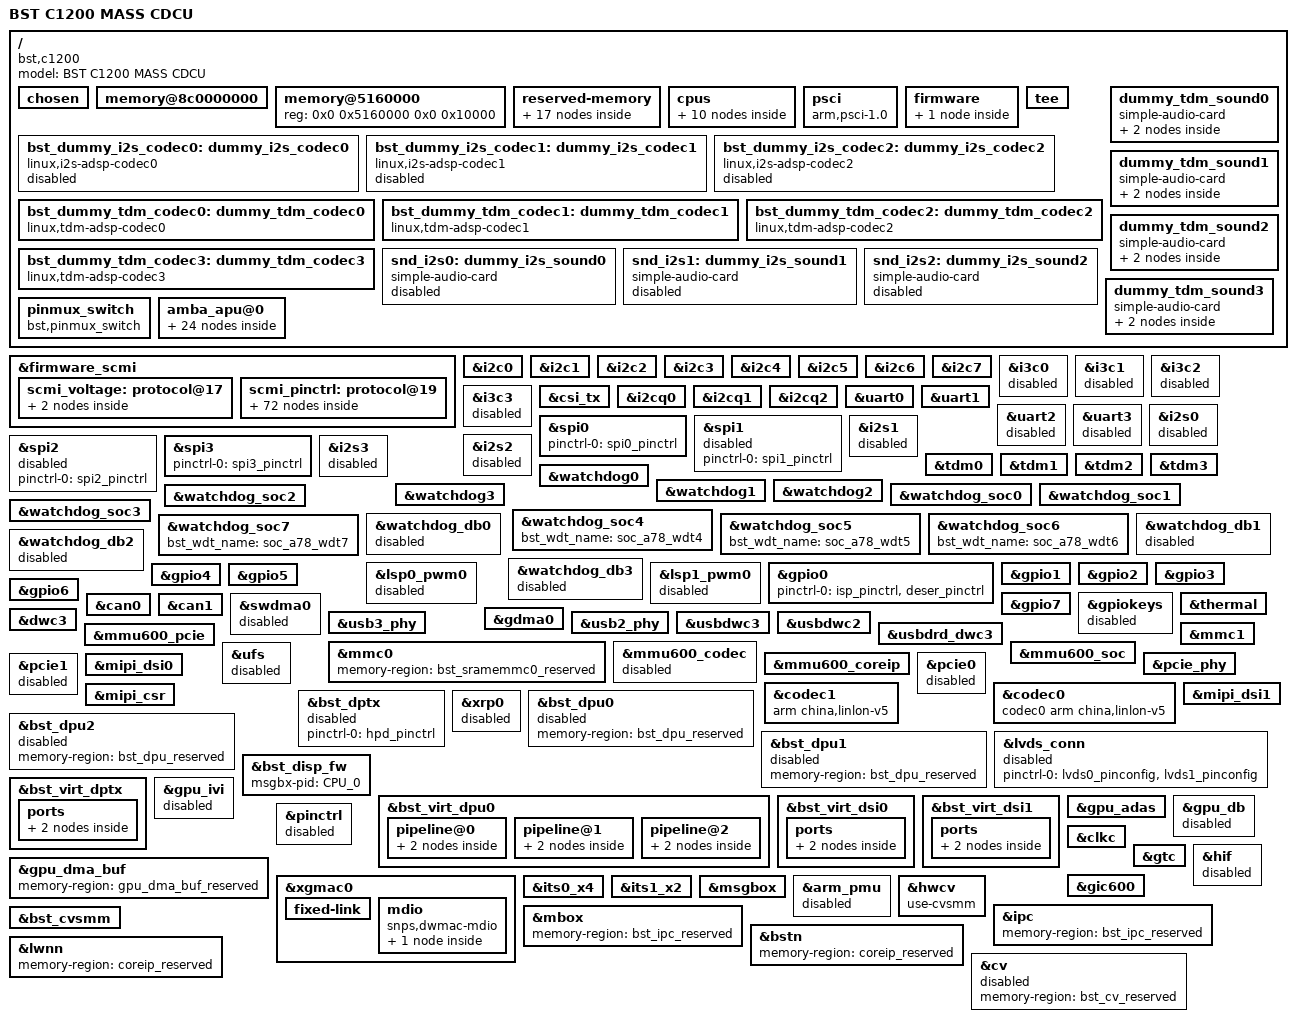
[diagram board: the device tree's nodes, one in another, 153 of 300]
// SPDX-License-Identifier: GPL-2.0+
/dts-v1/;
#include "bstc1200.dtsi"

/ {
	compatible = "bst,c1200";
	model = "BST C1200 MASS CDCU";

	chosen {
		bootargs = "earlycon=uart8250,mmio32,0x20008000 console=ttyS0,115200n8 rdinit=/sbin/init root=/dev/ram rw init=/linuxrc rodata=n";
		stdout-path = "uart0";
	};

	memory@8c0000000 {
		device_type = "memory";
		reg = < 0x8 0x10000000 0x0 0x30000000
			0x8 0xc0000000 0x1 0x0
			0xc 0x0 0x0 0x40000000
			0x8 0x254000 0x0 0x1000
			0x8 0x151000 0x0 0x1000
			0x8 0x1400000 0x0 0x1000000
			0x8 0x50000000 0x0 0x03000000
			0xc 0x50000000 0x0 0x03000000
		>;
	};

	// eMMC 64K
	memory@5160000 {
		device_type = "memory";
		reg = <0x0 0x5160000 0x0 0x10000>;
	};

	reserved-memory {
		#address-cells = <2>;
		#size-cells = <2>;
		ranges;

		scmi_buf_reserved: scmi_buf@800151000 {
			compatible = "shared-dma-pool";
			reg = <0x8 0x151000 0x0 0x1000>;
			no-map;
		};



		bst_nor_flash_code_reserved: bst_nor_flash@800130000 {
			compatible = "shared-dma-pool";
			reg = <0x8 0x130000 0x0 0x10000>;
			no-map;
		};


		bst_sramemmc0_reserved: bst_sramemmc0@5160000{
			compatible = "shared-dma-pool";
			reg = <0x0 0x5160000 0x0 0x10000>;
			no-map;
		};


		bst_sramemmc1_reserved: bst_sramemmc0@5170000{
			compatible = "shared-dma-pool";
			reg = <0x0 0x5170000 0x0 0x10000>;
			no-map;
		};

		bst_dpu_reserved: bst_dpu_cma@940000000 {
			compatible = "shared-dma-pool";
			reg = <0x9 0x40000000 0x0 0x4000000>;
			reusable;
		};

		/* gpu memory pool */
		gpu_dma_buf_reserved: gpu_cma@944000000 {
			compatible = "shared-dma-pool";
			align-shift = <8>;
			reg = <0x9 0x44000000 0x0 0x8000000>;
			reusable;
		};

		bst_ipc_reserved: bst_ipc@80ff00000 {
			compatible = "shared-dma-pool";
			reg = <0x8 0x0ff00000 0x0 0x100000>;
			no-map;
		};

		bstn_fw_code_reserved: bstn@810000000 {
			compatible = "shared-dma-pool";
			reg = <0x8 0x10000000 0x0 0x2000000>;
			no-map;
		};

		bst_lwnn_fw_code_reserved: bst_lwnn@812000000 {
			compatible = "shared-dma-pool";
			reg = <0x8 0x12000000 0x0 0x8000000>;
			no-map;
		};

		bst_cv_reserved: bst_cv_cma@81a000000 {
			compatible = "shared-dma-pool";
			reg = <0x8 0x1a000000 0x0 0x2000000>;
			align-shift = <8>;
			reusable;
		};

		bst_debug_reserved: bst_debug@81c000000 {
			compatible = "shared-dma-pool";
			reg = <0x8 0x1c000000 0x0 0x5000000>;
			no-map;
		};

		/* coreip public memory pool */
		coreip_reserved: coreip_pub_cma@c00000000 {
			compatible = "shared-dma-pool";
			align-shift = <8>;
			reg = <0xc 0x0 0x0 0x40000000>;
			reusable;
linux,cma-heap;
		};

		/* Reserved for exchange message between driver and firmware */
		isp_fw_msg_rsv: bst_isp_msg@821000000 {
			reg = <0x8 0x21000000 0x0 0x1000000>;
			no-map;
		};

		/* Reserved exclusively for firmware */
		isp_fw_buf_rsv: bst_isp_buf@822000000 {
			reg = <0x8 0x22000000 0x0 0x15000000>;
			no-map;
		};

		/*reserved for global secure dmabuf */
		global_dmabuf_secure_reserved: global_secure_dmabuf@850000000 {
			compatible = "shared-dma-pool";
			reg = <0x8 0x50000000 0x0 0x03000000
                   0xc 0x50000000 0x0 0x03000000
			>;
			no-map;
		};
		/*reserved for global normal dmabuf */
		global_dmabuf_normal_reserved: global_normal_dmabuf@837000000 {
			compatible = "shared-dma-pool";
			reg = <0x8 0x37000000 0x0 0x09000000>;
			no-map;
		};

		bst_optee_reserved: bst_optee@801400000 {
			compatible = "shared-dma-pool";
			reg = <0x8 0x1400000 0x0 0x1000000>;
			no-map;
		};
	};


/****************************************************************************************/
/*	c0_lockstep/c1_split	1 + 5: c0 0x0 + c0 0x100 \ c1 0x0 ~ 0x300
 *	c0_lockstep/c1_lockstep	1 + 3: c0 0x0 + c0 0x100 \ c1 0x0 ~ 0x100
 *	split			2 + 6: c0 0x0 ~ 0x100 + c0 0x200 ~ 0x300 \ c1 0x0 ~ 0x300
 *	split			4 + 4: c0 0x0 ~ 0x300 + c1 0x0 ~ 0x300
 */
/****************************************************************************************/
	cpus {
		#address-cells = <1>;
		#size-cells = <0>;

		/* cluster 0 */
		cpu_l0: cpu@0 {
			compatible = "arm,cortex-a78", "arm,armv8";
			device_type = "cpu";
			enable-method = "psci";
			next-level-cache = <&l2_0>;
			reg = <0x0>;
			freq-domain = <&cpufreq 0>;
		};
		cpu_l1: cpu@1 {
			compatible = "arm,cortex-a78", "arm,armv8";
			device_type = "cpu";
			enable-method = "psci";
			next-level-cache = <&l2_0>;
			reg = <0x100>;
			freq-domain = <&cpufreq 0>;
		};
		cpu_l2: cpu@2 {
			compatible = "arm,cortex-a78", "arm,armv8";
			device_type = "cpu";
			enable-method = "psci";
			next-level-cache = <&l2_0>;
			reg = <0x200>;
			freq-domain = <&cpufreq 0>;
		};
		cpu_l3: cpu@3 {
			compatible = "arm,cortex-a78", "arm,armv8";
			device_type = "cpu";
			enable-method = "psci";
			next-level-cache = <&l2_0>;
			reg = <0x300>;
			freq-domain = <&cpufreq 0>;
		};
		l2_0: l2-cache-0 {
			compatible = "cache";
		};
                /* cluster 1 */
                cpu_b0: cpu@100 {
                        compatible = "arm,cortex-a78", "arm,armv8";
                        device_type = "cpu";
                        enable-method = "psci";
                        next-level-cache = <&l2_1>;
                        reg = <0x10000>;
			freq-domain = <&cpufreq 1>;
                };
                cpu_b1: cpu@101 {
                        compatible = "arm,cortex-a78", "arm,armv8";
                        device_type = "cpu";
                        enable-method = "psci";
                        next-level-cache = <&l2_1>;
                        reg = <0x10100>;
			freq-domain = <&cpufreq 1>;
                };
                cpu_b2: cpu@102 {
                        compatible = "arm,cortex-a78", "arm,armv8";
                        device_type = "cpu";
                        enable-method = "psci";
                        next-level-cache = <&l2_1>;
                        reg = <0x10200>;
			freq-domain = <&cpufreq 1>;
                };
                cpu_b3: cpu@103 {
                        compatible = "arm,cortex-a78", "arm,armv8";
                        device_type = "cpu";
                        enable-method = "psci";
                        next-level-cache = <&l2_1>;
                        reg = <0x10300>;
			freq-domain = <&cpufreq 1>;
                };

                l2_1: l2-cache-1 {
                        compatible = "cache";
                };

	};

	psci {
		compatible	= "arm,psci-1.0";
		method		= "smc";
		cpu_on		= <0xC4000003>;
		cpu_off		= <0x84000002>;
		cpu_suspend	= <0xC4000001>;
	};



	firmware {
		optee {
                compatible = "linaro,optee-tz";
                method = "smc";
                chip-number = <2>;
        };
	};

	tee {
		#address-cells = <0x2>;
		#size-cells = <0x2>;
		reg = <0x0 0x18060000 0x0 0x1f000>;
		memory-region = <&bst_optee_reserved>;
		mbox-names = "bst-mbox";
		chip-number = <2>;
	};

    bst_dummy_i2s_codec0:dummy_i2s_codec0 {
         compatible = "linux,i2s-adsp-codec0";
         #sound-dai-cells = <0>;
         status = "disable";
    };
    bst_dummy_i2s_codec1:dummy_i2s_codec1 {
         compatible = "linux,i2s-adsp-codec1";
         #sound-dai-cells = <0>;
         status = "disable";
    };

    bst_dummy_i2s_codec2:dummy_i2s_codec2 {
         compatible = "linux,i2s-adsp-codec2";
         #sound-dai-cells = <0>;
         status = "disable";
    };

    bst_dummy_tdm_codec0:dummy_tdm_codec0 {
         compatible = "linux,tdm-adsp-codec0";
         #sound-dai-cells = <0>;
         status = "okay";
    };

    bst_dummy_tdm_codec1:dummy_tdm_codec1 {
         compatible = "linux,tdm-adsp-codec1";
         #sound-dai-cells = <0>;
         status = "okay";
    };

    bst_dummy_tdm_codec2:dummy_tdm_codec2 {
         compatible = "linux,tdm-adsp-codec2";
         #sound-dai-cells = <0>;
         status = "okay";
    };

    bst_dummy_tdm_codec3:dummy_tdm_codec3 {
         compatible = "linux,tdm-adsp-codec3";
         #sound-dai-cells = <0>;
         status = "okay";
    };

    snd_i2s0:dummy_i2s_sound0 {
        status = "disable";
        compatible = "simple-audio-card";
        simple-audio-card,format = "i2s";
        simple-audio-card,name = "everest,dummy-codec-i2s0";
        simple-audio-card,mclk-fs = <256>;
        //simple-audio-card,bitclock-master = <&sndcodec0>;
        //simple-audio-card,frame-master = <&sndcodec0>;
    };

    snd_i2s1:dummy_i2s_sound1 {
        status = "disable";
        compatible = "simple-audio-card";
        simple-audio-card,format = "i2s";
        simple-audio-card,name = "everest,dummy-codec-i2s1";
        simple-audio-card,mclk-fs = <256>;
    };

    snd_i2s2:dummy_i2s_sound2 {
        status = "disable";
        compatible = "simple-audio-card";
        simple-audio-card,format = "i2s";
        simple-audio-card,name = "everest,dummy-codec-i2s2";
        simple-audio-card,mclk-fs = <256>;
        //simple-audio-card,bitclock-master = <&sndcodec1>;
        //simple-audio-card,frame-master = <&sndcodec1>;
    };

    dummy_tdm_sound0 {
        status = "okay";
        compatible = "simple-audio-card";
        simple-audio-card,format = "i2s";
        simple-audio-card,name = "everest,dummy-codec-tdm0";
        simple-audio-card,mclk-fs = <256>;

        simple-audio-card,cpu {
            sound-dai = <&tdm0>;
        };

        simple-audio-card,codec {
            sound-dai = <&bst_dummy_tdm_codec0>;
        };
    };

    dummy_tdm_sound1 {
        status = "okay";
        compatible = "simple-audio-card";
        simple-audio-card,format = "i2s";
        simple-audio-card,name = "everest,dummy-codec-tdm1";
        simple-audio-card,mclk-fs = <256>;

        simple-audio-card,cpu {
            sound-dai = <&tdm1>;
        };

        simple-audio-card,codec {
            sound-dai = <&bst_dummy_tdm_codec1>;
        };
    };

    dummy_tdm_sound2 {
        status = "okay";
        compatible = "simple-audio-card";
        simple-audio-card,format = "i2s";
        simple-audio-card,name = "everest,dummy-codec-tdm2";
        simple-audio-card,mclk-fs = <256>;

        simple-audio-card,cpu {
            sound-dai = <&tdm2>;
        };

        simple-audio-card,codec {
            sound-dai = <&bst_dummy_tdm_codec2>;
        };
    };

    dummy_tdm_sound3 {
        status = "okay";
        compatible = "simple-audio-card";
        simple-audio-card,format = "i2s";
        simple-audio-card,name = "everest,dummy-codec-tdm3";
        simple-audio-card,mclk-fs = <256>;

        simple-audio-card,cpu {
            sound-dai = <&tdm3>;
        };

        simple-audio-card,codec {
            sound-dai = <&bst_dummy_tdm_codec3>;
        };
    };
	pinmux_switch {
		compatible = "bst,pinmux_switch";
		status = "okay";

		pinctrl-names = "switch_on", "switch_off", \
						"i2c0_mode", "i3c0_mode", \
						"i2c1_mode", "i3c1_mode", \
						"i2c2_mode", "i3c2_mode", \
						"i2c3_mode", "i3c3_mode", \
						"i2c4_mode", "i3c40_mode", \
						"i2c5_mode", "i2cq0_mode", \
						"i2c6_mode", "i2cq1_mode", \
						"i2c7_mode", "i2cq2_mode", \
						"i2s0_on", "i2s1_on", "i2s2_on", \
						"tdm0_on", "tdm1_on", "tdm2_on", "tdm3_on";
		pinctrl-0 = <&debug1_pinctrl>;
		pinctrl-1 = <&debug2_pinctrl>;
		pinctrl-2 = <&i2c0_pinctrl>;
		pinctrl-3 = <&i3c0_pinctrl>;
		pinctrl-4 = <&i2c1_pinctrl>;
		pinctrl-5 = <&i3c1_pinctrl>;
		pinctrl-6 = <&i2c2_pinctrl>;
		pinctrl-7 = <&i3c2_pinctrl>;
		pinctrl-8 = <&i2c3_pinctrl>;
		pinctrl-9 = <&i3c3_pinctrl>;
		pinctrl-10 = <&i2c4_pinctrl>;
		pinctrl-11 = <&i3c40_pinctrl>;
		pinctrl-12 = <&i2c5_pinctrl>;
		pinctrl-13 = <&i2cq0_pinctrl>;
		pinctrl-14 = <&i2c6_pinctrl>;
		pinctrl-15 = <&i2cq1_pinctrl>;
		pinctrl-16 = <&i2c7_pinctrl>;
		pinctrl-17 = <&i2cq2_pinctrl>;
		pinctrl-18 = <&i2s0_pinctrl>;
		pinctrl-19 = <&i2s1_pinctrl>;
		pinctrl-20 = <&i2s2_pinctrl>;
		pinctrl-21 = <&tdm0_pinctrl>;
		pinctrl-22 = <&tdm1_pinctrl>;
		pinctrl-23 = <&tdm2_pinctrl>;
		pinctrl-24 = <&tdm3_pinctrl>;
	};

	amba_apu@0 {
		//i2c cycleloop mode A start
		i2ca0: i2ca0 {
			#address-cells = <1>;
			#size-cells = <0>;
			compatible = "snps,designware-i2c";
			reg = <0x0 0x20001000 0 0x1000>;
			interrupt-parent = <&gic600>;
			interrupts = <GIC_SPI 202 IRQ_TYPE_LEVEL_HIGH>;
			clock-frequency = <3400000>;
			i2c-sda-hold-time-ns = <10>;
			i2c-sda-falling-time-ns = <5>;
			i2c-scl-falling-time-ns = <5>;
			clocks= <&scmi_clk GATE_LSP0_I2C0_PCLK_EN>,
				<&scmi_clk GATE_LSP0_I2C0_WCLK_EN>;
			clock-names = "pclk","wclk";
			resets = <&scmi_reset RST_LSP0_I2C0_WCLK_SW>;
			reset-names = "i2c0_reset";
			i2c-nr = <0>;
			status = "disable";
		};

		i2ca1: i2ca1 {
			#address-cells = <1>;
			#size-cells = <0>;
			compatible = "snps,designware-i2c";
			reg = <0x0 0x20002000 0 0x1000>;
			interrupt-parent = <&gic600>;
			interrupts = <GIC_SPI 203 IRQ_TYPE_LEVEL_HIGH>;
			clock-frequency = <3400000>;
			i2c-sda-hold-time-ns = <10>;
			i2c-sda-falling-time-ns = <5>;
			i2c-scl-falling-time-ns = <5>;
			clocks= <&scmi_clk GATE_LSP0_I2C1_PCLK_EN>,
				<&scmi_clk GATE_LSP0_I2C1_WCLK_EN>;
			clock-names = "pclk","wclk";
			resets = <&scmi_reset RST_LSP0_I2C1_WCLK_SW>;
			reset-names = "i2c0_reset";
			i2c-nr = <1>;
			status = "disable";
			i2c-slave-eeprom@64 {
				compatible = "slave-24c02";
				reg = <0x40000064>;
			};
		};

		i2ca2: i2ca2 {
			#address-cells = <1>;
			#size-cells = <0>;
			compatible = "snps,designware-i2c";
			reg = <0x0 0x20003000 0 0x1000>;
			interrupt-parent = <&gic600>;
			interrupts = <GIC_SPI 204 IRQ_TYPE_LEVEL_HIGH>;
			clock-frequency = <3400000>;
			i2c-sda-hold-time-ns = <10>;
			i2c-sda-falling-time-ns = <5>;
			i2c-scl-falling-time-ns = <5>;
			clocks= <&scmi_clk GATE_LSP0_I2C2_PCLK_EN>,
				<&scmi_clk GATE_LSP0_I2C2_WCLK_EN>;
			clock-names = "pclk","wclk";
			resets = <&scmi_reset RST_LSP0_I2C2_WCLK_SW>;
			reset-names = "i2c0_reset";

			i2c-nr = <2>;
			status = "disable";
		};

		i2ca3: i2ca3 {
			#address-cells = <1>;
			#size-cells = <0>;
			compatible = "snps,designware-i2c";
			reg = <0x0 0x20004000 0 0x1000>;
			interrupt-parent = <&gic600>;
			interrupts = <GIC_SPI 205 IRQ_TYPE_LEVEL_HIGH>;
			clock-frequency = <3400000>;
			i2c-sda-hold-time-ns = <10>;
			i2c-sda-falling-time-ns = <5>;
			i2c-scl-falling-time-ns = <5>;
			clocks= <&scmi_clk GATE_LSP0_I2C3_PCLK_EN>,
				<&scmi_clk GATE_LSP0_I2C3_WCLK_EN>;
			clock-names = "pclk","wclk";
			resets = <&scmi_reset RST_LSP0_I2C3_WCLK_SW>;
			reset-names = "i2c0_reset";
			i2c-nr = <3>;
			status = "disable";
			i2c-slave-eeprom@64 {
				compatible = "slave-24c02";
				reg = <0x40000064>;
			};
		};

		i2ca4: i2ca4 {
			#address-cells = <1>;
			#size-cells = <0>;
			compatible = "snps,designware-i2c";
			reg = <0x0 0x20021000 0 0x1000>;
			interrupt-parent = <&gic600>;
			interrupts = <GIC_SPI 237 IRQ_TYPE_LEVEL_HIGH>;
			clock-frequency = <3400000>;
			i2c-sda-hold-time-ns = <10>;
			i2c-sda-falling-time-ns = <5>;
			i2c-scl-falling-time-ns = <5>;
			clocks= <&scmi_clk GATE_LSP1_I2C0_PCLK_EN>,
				<&scmi_clk GATE_LSP1_I2C0_WCLK_EN>;
			clock-names = "pclk","wclk";
			resets = <&scmi_reset RST_LSP1_I2C0_WCLK_SW>;
			reset-names = "i2c0_reset";
			i2c-nr = <4>;
			status = "disable";
		};

		i2ca5: i2ca5 {
			#address-cells = <1>;
			#size-cells = <0>;
			compatible = "snps,designware-i2c";
			reg = <0x0 0x20022000 0 0x1000>;
			interrupt-parent = <&gic600>;
			interrupts = <GIC_SPI 238 IRQ_TYPE_LEVEL_HIGH>;
			clock-frequency = <3400000>;
			i2c-sda-hold-time-ns = <10>;
			i2c-sda-falling-time-ns = <5>;
			i2c-scl-falling-time-ns = <5>;
			clocks= <&scmi_clk GATE_LSP1_I2C1_PCLK_EN>,
				<&scmi_clk GATE_LSP1_I2C1_WCLK_EN>;
			clock-names = "pclk","wclk";
			resets = <&scmi_reset RST_LSP1_I2C1_WCLK_SW>;
			reset-names = "i2c0_reset";
			i2c-nr = <5>;
			status = "disable";
			i2c-slave-eeprom@64 {
				compatible = "slave-24c02";
				reg = <0x40000064>;
			};
		};

		i2ca6: i2ca6 {
			#address-cells = <1>;
			#size-cells = <0>;
			compatible = "snps,designware-i2c";
			reg = <0x0 0x20023000 0 0x1000>;
			interrupt-parent = <&gic600>;
			interrupts = <GIC_SPI 239 IRQ_TYPE_LEVEL_HIGH>;
			clock-frequency = <3400000>;
			i2c-sda-hold-time-ns = <10>;
			i2c-sda-falling-time-ns = <5>;
			i2c-scl-falling-time-ns = <5>;
			clocks= <&scmi_clk GATE_LSP1_I2C2_PCLK_EN>,
			<&scmi_clk GATE_LSP1_I2C2_WCLK_EN>;
			clock-names = "pclk","wclk";
			resets = <&scmi_reset RST_LSP1_I2C2_WCLK_SW>;
			reset-names = "i2c0_reset";
			i2c-nr = <6>;
			status = "disable";
		};

		i2ca7: i2ca7 {
			#address-cells = <1>;
			#size-cells = <0>;
			compatible = "snps,designware-i2c";
			reg = <0x0 0x20024000 0 0x1000>;
			interrupt-parent = <&gic600>;
			interrupts = <GIC_SPI 240 IRQ_TYPE_LEVEL_HIGH>;
			clock-frequency = <3400000>;
			i2c-sda-hold-time-ns = <10>;
			i2c-sda-falling-time-ns = <5>;
			i2c-scl-falling-time-ns = <5>;
			clocks= <&scmi_clk GATE_LSP1_I2C3_PCLK_EN>,
			<&scmi_clk GATE_LSP1_I2C3_WCLK_EN>;
			clock-names = "pclk","wclk";
			resets = <&scmi_reset RST_LSP1_I2C3_WCLK_SW>;
			reset-names = "i2c0_reset";
			i2c-nr = <7>;
			status = "disable";
			i2c-slave-eeprom@64 {
				compatible = "slave-24c02";
				reg = <0x40000064>;
			};
		};
		//i2c cycleloop mode A end
		//i2c cycleloop mode B start
		i2cb0: i2cb0 {
			#address-cells = <1>;
			#size-cells = <0>;
			compatible = "snps,designware-i2c";
			reg = <0x0 0x20001000 0 0x1000>;
			interrupt-parent = <&gic600>;
			interrupts = <GIC_SPI 202 IRQ_TYPE_LEVEL_HIGH>;
			clock-frequency = <3400000>;
			i2c-sda-hold-time-ns = <10>;
			i2c-sda-falling-time-ns = <5>;
			i2c-scl-falling-time-ns = <5>;
			clocks= <&scmi_clk GATE_LSP0_I2C0_PCLK_EN>,
				<&scmi_clk GATE_LSP0_I2C0_WCLK_EN>;
			clock-names = "pclk","wclk";
			resets = <&scmi_reset RST_LSP0_I2C0_WCLK_SW>;
			reset-names = "i2c0_reset";
			i2c-nr = <0>;
			status = "disable";
			i2c-slave-eeprom@64 {
				compatible = "slave-24c02";
				reg = <0x40000064>;
			};
		};

		i2cb1: i2cb1 {
			#address-cells = <1>;
			#size-cells = <0>;
			compatible = "snps,designware-i2c";
			reg = <0x0 0x20002000 0 0x1000>;
			interrupt-parent = <&gic600>;
			interrupts = <GIC_SPI 203 IRQ_TYPE_LEVEL_HIGH>;
			clock-frequency = <3400000>;
			i2c-sda-hold-time-ns = <10>;
			i2c-sda-falling-time-ns = <5>;
			i2c-scl-falling-time-ns = <5>;
			clocks= <&scmi_clk GATE_LSP0_I2C1_PCLK_EN>,
			<&scmi_clk GATE_LSP0_I2C1_WCLK_EN>;
			clock-names = "pclk","wclk";
			resets = <&scmi_reset RST_LSP0_I2C1_WCLK_SW>;
			reset-names = "i2c0_reset";
			i2c-nr = <1>;
			status = "disable";
		};

		i2cb2: i2cb2 {
			#address-cells = <1>;
			#size-cells = <0>;
			compatible = "snps,designware-i2c";
			reg = <0x0 0x20003000 0 0x1000>;
			interrupt-parent = <&gic600>;
			interrupts = <GIC_SPI 204 IRQ_TYPE_LEVEL_HIGH>;
			clock-frequency = <3400000>;
			i2c-sda-hold-time-ns = <10>;
			i2c-sda-falling-time-ns = <5>;
			i2c-scl-falling-time-ns = <5>;
			clocks= <&scmi_clk GATE_LSP0_I2C2_PCLK_EN>,
			<&scmi_clk GATE_LSP0_I2C2_WCLK_EN>;
			clock-names = "pclk","wclk";
			resets = <&scmi_reset RST_LSP0_I2C2_WCLK_SW>;
			reset-names = "i2c0_reset";
			i2c-nr = <2>;
			status = "disable";
			i2c-slave-eeprom@64 {
				compatible = "slave-24c02";
				reg = <0x40000064>;
			};
		};

		i2cb3: i2cb3 {
			#address-cells = <1>;
			#size-cells = <0>;
			compatible = "snps,designware-i2c";
			reg = <0x0 0x20004000 0 0x1000>;
			interrupt-parent = <&gic600>;
			interrupts = <GIC_SPI 205 IRQ_TYPE_LEVEL_HIGH>;
			clock-frequency = <3400000>;
			i2c-sda-hold-time-ns = <10>;
			i2c-sda-falling-time-ns = <5>;
			i2c-scl-falling-time-ns = <5>;
			clocks= <&scmi_clk GATE_LSP0_I2C3_PCLK_EN>,
			<&scmi_clk GATE_LSP0_I2C3_WCLK_EN>;
			clock-names = "pclk","wclk";
			resets = <&scmi_reset RST_LSP0_I2C3_WCLK_SW>;
			reset-names = "i2c0_reset";
			i2c-nr = <3>;
			status = "disable";
		};

		i2cb4: i2cb4 {
			#address-cells = <1>;
			#size-cells = <0>;
			compatible = "snps,designware-i2c";
			reg = <0x0 0x20021000 0 0x1000>;
			interrupt-parent = <&gic600>;
			interrupts = <GIC_SPI 237 IRQ_TYPE_LEVEL_HIGH>;
			clock-frequency = <3400000>;
			i2c-sda-hold-time-ns = <10>;
			i2c-sda-falling-time-ns = <5>;
			i2c-scl-falling-time-ns = <5>;
			clocks= <&scmi_clk GATE_LSP1_I2C0_PCLK_EN>,
			<&scmi_clk GATE_LSP1_I2C0_WCLK_EN>;
			clock-names = "pclk","wclk";
			resets = <&scmi_reset RST_LSP1_I2C0_WCLK_SW>;
			reset-names = "i2c0_reset";
			i2c-nr = <4>;
			status = "disable";
			i2c-slave-eeprom@64 {
				compatible = "slave-24c02";
				reg = <0x40000064>;
			};
		};

		i2cb5: i2cb5 {
			#address-cells = <1>;
			#size-cells = <0>;
			compatible = "snps,designware-i2c";
			reg = <0x0 0x20022000 0 0x1000>;
			interrupt-parent = <&gic600>;
			interrupts = <GIC_SPI 238 IRQ_TYPE_LEVEL_HIGH>;
			clock-frequency = <3400000>;
			i2c-sda-hold-time-ns = <10>;
			i2c-sda-falling-time-ns = <5>;
			i2c-scl-falling-time-ns = <5>;
			clocks= <&scmi_clk GATE_LSP1_I2C1_PCLK_EN>,
			<&scmi_clk GATE_LSP1_I2C1_WCLK_EN>;
			clock-names = "pclk","wclk";
			resets = <&scmi_reset RST_LSP1_I2C1_WCLK_SW>;
			reset-names = "i2c0_reset";
			i2c-nr = <5>;
			status = "disable";
		};

		i2cb6: i2cb6 {
			#address-cells = <1>;
			#size-cells = <0>;
			compatible = "snps,designware-i2c";
			reg = <0x0 0x20023000 0 0x1000>;
			interrupt-parent = <&gic600>;
			interrupts = <GIC_SPI 239 IRQ_TYPE_LEVEL_HIGH>;
			clock-frequency = <3400000>;
			i2c-sda-hold-time-ns = <10>;
			i2c-sda-falling-time-ns = <5>;
			i2c-scl-falling-time-ns = <5>;
			clocks= <&scmi_clk GATE_LSP1_I2C2_PCLK_EN>,
			<&scmi_clk GATE_LSP1_I2C2_WCLK_EN>;
			clock-names = "pclk","wclk";
			resets = <&scmi_reset RST_LSP1_I2C2_WCLK_SW>;
			reset-names = "i2c0_reset";
			i2c-nr = <6>;
			status = "disable";
			i2c-slave-eeprom@64 {
				compatible = "slave-24c02";
				reg = <0x40000064>;
			};
		};

		i2cb7: i2cb7 {
			#address-cells = <1>;
			#size-cells = <0>;
			compatible = "snps,designware-i2c";
			reg = <0x0 0x20024000 0 0x1000>;
			interrupt-parent = <&gic600>;
			interrupts = <GIC_SPI 240 IRQ_TYPE_LEVEL_HIGH>;
			clock-frequency = <3400000>;
			i2c-sda-hold-time-ns = <10>;
			i2c-sda-falling-time-ns = <5>;
			i2c-scl-falling-time-ns = <5>;
			clocks= <&scmi_clk GATE_LSP1_I2C3_PCLK_EN>,
			<&scmi_clk GATE_LSP1_I2C3_WCLK_EN>;
			clock-names = "pclk","wclk";
			resets = <&scmi_reset RST_LSP1_I2C3_WCLK_SW>;
			reset-names = "i2c0_reset";
			i2c-nr = <7>;
			status = "disable";
		};
		//i2c cycleloop mode B end
	};
};



&firmware_scmi {

		shmem = <&scmi_buf_reserved>;
		reg = <0x0 0x20011014 0 0x14>;
		status = "okay";

		scmi_voltage: protocol@17 {

			regulators {
				#address-cells = <1>;
				#size-cells = <0>;
				v_qmmc: regulator {
					reg = <0>;
					regulator-name = "voltage_qmmc";
					regulator-min-microvolt = <1800000>;
					regulator-max-microvolt = <3300000>;
					regulator-always-on;
				};
			};
		};


		scmi_pinctrl: protocol@19 {
			sd_pinctrl:sd_pinctrl {
				mux {
					pins = "SC_SDMMC1_WP", "SC_SDMMC1_CDN","SC_SDMMC1_RSTB","SC_SDMMC1_STROBE","SC_SDMMC1_RSTB","SC_SDMMC1_CLK","SC_SDMMC1_CMD"
					,"SC_SDMMC1_DAT0","SC_SDMMC1_DAT1","SC_SDMMC1_DAT2","SC_SDMMC1_DAT3";
					function = "sdmmc1";
				};
			};
			isp_pinctrl:isp_pinctrl {
				mux {
					pins = "WK_GPIO33", "WK_GPIO34","WK_GPIO35";
					function = "isp";
				};
			};
			deser_pinctrl: deser_pinctrl {
				mux {
					pins = "WK_GPIO15", "WK_GPIO20","WK_GPIO21";
					function = "gpio";
				};
			};
			i2c0_pinctrl:i2c0_pinctrl {
				mux {
					pins = "SC_I2C0_SCL", "SC_I2C0_SDA";
					function = "i2c0";
				};
			};
			i2c1_pinctrl:i2c1_pinctrl {
				mux {
					pins = "SC_I2C1_SCL", "SC_I2C1_SDA";
					function = "i2c1";
				};
			};
			i2c2_pinctrl:i2c2_pinctrl {
				mux {
					pins = "SC_I2C2_SCL", "SC_I2C2_SDA";
					function = "i2c2";
				};
			};
			i2c3_pinctrl:i2c3_pinctrl {
				mux {
					pins = "SC_I2C3_SCL", "SC_I2C3_SDA";
					function = "i2c3";
				};
			};
			i2c4_pinctrl:i2c4_pinctrl {
				mux {
					pins = "SC_I2C4_SCL", "SC_I2C4_SDA";
					function = "i2c4";
				};
			};
			i2c5_pinctrl:i2c5_pinctrl {
				mux {
					pins = "SC_I2C5_SCL", "SC_I2C5_SDA";
					function = "i2c5";
				};
			};
			i2cq0_pinctrl:i2cq0_pinctrl {
				mux {
					pins = "SC_I2C5_SCL", "SC_I2C5_SDA";
					function = "isp";
				};
			};
			i2c6_pinctrl:i2c6_pinctrl {
				mux {
					pins = "SC_I2C6_SCL", "SC_I2C6_SDA";
					function = "i2c6";
				};
			};
			i2cq1_pinctrl:i2cq1_pinctrl {
				mux {
					pins = "SC_I2C6_SCL", "SC_I2C6_SDA";
					function = "isp";
				};
			};
			i2c7_pinctrl:i2c7_pinctrl {
				mux {
					pins = "SC_I2C7_SCL", "SC_I2C7_SDA";
					function = "i2c7";
				};
			};
			i2cq2_pinctrl:i2cq2_pinctrl {
				mux {
					pins = "SC_I2C7_SCL", "SC_I2C7_SDA";
					function = "isp";
				};
			};
            i3c40_pinctrl:i3c40_pinctrl {
                mux {
                    pins = "SC_I2C4_SCL", "SC_I2C4_SDA";
                    function = "i3c0";
                };
            };
            i3c0_pinctrl:i3c0_pinctrl {
                mux {
                    pins = "SC_I2C0_SCL", "SC_I2C0_SDA";
                    function = "i3c0";
                };
            };
            i3c1_pinctrl:i3c1_pinctrl {
                mux {
                    pins = "SC_I2C1_SCL", "SC_I2C1_SDA";
                    function = "i3c1";
                };
            };
            i3c2_pinctrl:i3c2_pinctrl {
                mux {
                    pins = "SC_I2C2_SCL", "SC_I2C2_SDA";
                    function = "i3c2";
                };
            };
            i3c3_pinctrl:i3c3_pinctrl {
                mux {
                    pins = "SC_I2C3_SCL", "SC_I2C3_SDA";
                    function = "i3c3";
                };
            };
			debug1_pinctrl:debug1_pinctrl {
				mux {
					pins = "SC_UART2_TXD";
					function = "xgmac";
				};
			};
			debug2_pinctrl:debug2_pinctrl {
				mux {
					pins = "SC_UART2_TXD";
					function = "uart2";
				};
			};
			hpd_pinctrl:hpd_pinctrl {
				mux {
					pins = "EDP_HPD";
					function = "edp";
				};
			};
			lvds0_pinconfig:lvds0_pinconfig {
				config {
					pins = "LVDS0_ODD_TX0", "LVDS0_ODD_TX1", "LVDS0_ODD_TX2", "LVDS0_ODD_TX3", "LVDS0_ODD_CLKN";
					input-enable;
				};
			};
			lvds1_pinconfig:lvds1_pinconfig {
				config {
					pins = "LVDS0_EVEN_TX0", "LVDS0_EVEN_TX1", "LVDS0_EVEN_TX2", "LVDS0_EVEN_TX3", "LVDS0_EVEN_CLKN";
					input-enable;
				};
			};
			i2s0_pinctrl:i2s0_pinctrl  {
				mux {
				pins = "SC_I2S0_SCK", "SC_I2S0_WS", "SC_I2S0_DIN0", "SC_I2S0_DOUT0";
				function = "i2s0";
				};
			};
			i2s1_pinctrl:i2s1_pinctrl  {
				mux {
				pins = "SC_I2S1_MCK", "SC_I2S1_SCK", "SC_I2S1_WS", "SC_I2S1_DIN0", "SC_I2S1_DOUT0";
				function = "i2s1";
				};
			};
			i2s2_pinctrl:i2s2_pinctrl  {
				mux {
				pins = "SC_I2S2_SCK", "SC_I2S2_WS", "SC_I2S2_DIN0", "SC_I2S2_DOUT0";
				function = "i2s2";
				};
			};
			tdm0_pinctrl:tdm0_pinctrl  {
				mux {
				pins = "SC_I2S0_SCK", "SC_I2S0_WS", "SC_I2S0_DIN0", "SC_I2S0_DOUT0";
				function = "pcm0";
				};
			};
			tdm1_pinctrl:tdm1_pinctrl  {
				mux {
				pins = "SC_I2S1_SCK", "SC_I2S1_WS", "SC_I2S1_DIN0", "SC_I2S1_DOUT0";
				function = "pcm1";
				};
			};
			tdm2_pinctrl:tdm2_pinctrl  {
				mux {
				pins = "SC_I2S2_SCK", "SC_I2S2_WS", "SC_I2S2_DIN0", "SC_I2S2_DOUT0";
				function = "pcm2";
				};
			};
			tdm3_pinctrl:tdm3_pinctrl  {
				mux {
				pins = "WK_GPIO16", "WK_GPIO17", "WK_GPIO18", "WK_GPIO19";
				function = "pcm3";
				};
			};
            i3c_pinconfig:i3c_pinconfig {
                config {
                    pins = "SC_I2C0_SCL", "SC_I2C0_SDA", "SC_I2C1_SCL", "SC_I2C1_SDA", "SC_I2C2_SCL", "SC_I2C2_SDA", "SC_I2C3_SCL", "SC_I2C3_SDA", "SC_I2C4_SCL", "SC_I2C4_SDA";
                    drive-strength = <12>;
                };
            };

			spi0_pinctrl:spi0_pinctrl {
				mux {
					pins = "WK_GPIO38", "WK_GPIO39", "WK_GPIO40", "WK_GPIO41";
					function = "spim0";
				};
			};

			spi1_pinctrl:spi1_pinctrl {
				mux {
					pins = "WK_GPIO38", "WK_GPIO39", "WK_GPIO40", "WK_GPIO41";
					function = "spis0";
				};
			};

			spi2_pinctrl:spi2_pinctrl {
				mux {
					pins = "WK_GPIO42", "WK_GPIO43", "ISP_FSYNC0", "ISP_FSYNC1";
					function = "spim1";
				};
			};

			spi3_pinctrl:spi3_pinctrl {
				mux {
					pins = "WK_GPIO42", "WK_GPIO43", "ISP_FSYNC0", "ISP_FSYNC1";
					function = "spis1";
				};
			};
		};
};

&i2c0 {
	status = "okay";
};

&i2c1 {
	status = "okay";
};

&i2c2 {
	status = "okay";
};

&i2c3 {
	status = "okay";
};

&i2c4 {
	status = "okay";
};

&i2c5 {
	status = "okay";
};

&i2c6 {
	status = "okay";
};

&i2c7 {
	status = "okay";
};

&i3c0 {
    status = "disable";
    // pinctrl-names = "default";
    // pinctrl-0 = <&i3c_pinconfig &i3c40_pinctrl>;
    // temp_sensor0: p3t1755@236152a0090 {
    //     reg = <0x0 0x236 0x152a0090>;
    //         compatible = "nxp,p3t1755dp";
    //         status = "okay";
    // };
};

&i3c1 {
    status = "disable";
    // pinctrl-names = "default";
    // pinctrl-0 = <&i3c_pinconfig &i3c1_pinctrl>;
    // temp_sensor1: p3t1755@236152a0090 {
    //     reg = <0x0 0x236 0x152a0090>;
    // };
};

&i3c2 {
    status = "disable";
	// compatible = "silvaco,i3c-slave";
    // pinctrl-names = "default";
    // pinctrl-0 = <&i3c_pinconfig &i3c2_pinctrl>;
};

&i3c3 {
       status = "disable";
};

&csi_tx {
       status = "okay";
       lane-speed = <1200>;
       vc-num = <1>;
};

&i2cq0 {
	status = "okay";
};
&i2cq1 {
	status = "okay";
};
&i2cq2 {
	status = "okay";
};

&uart0 {
	status = "okay";
};
&uart1 {
	status = "okay";
};
&uart2 {
	status = "disable";
};
&uart3 {
	status = "disable";
};

&spi0 {
	pinctrl-names = "default";
	pinctrl-0 = <&spi0_pinctrl>;
	status = "okay";
};
&spi1 {
	pinctrl-names = "default";
	pinctrl-0 = <&spi1_pinctrl>;
	status = "disable";
};
&spi2 {
	pinctrl-names = "default";
	pinctrl-0 = <&spi2_pinctrl>;
	status = "disable";
};
&spi3 {
	pinctrl-names = "default";
	pinctrl-0 = <&spi3_pinctrl>;
	status = "okay";
};

&i2s0 {
	//slave-mode;
	status = "disable";
	//pinctrl-names = "default";
	//pinctrl-0 = <&i2s0_pinctrl>;
};
&i2s1 {
	status = "disable";
	//pinctrl-names = "default";
	//pinctrl-0 = <&i2s1_pinctrl>;
};
&i2s2 {
	//slave-mode;
	status = "disable";
	//pinctrl-names = "default";
	//pinctrl-0 = <&i2s2_pinctrl>;
};
&i2s3 {
	status = "disable";
};

&tdm0 {
	status = "okay";
};
&tdm1 {
	status = "okay";
};
&tdm2 {
	status = "okay";
};
&tdm3 {
	status = "okay";
};

&watchdog0 {
	status = "okay";
};
&watchdog1 {
	status = "okay";
};
&watchdog2 {
	status = "okay";
};
&watchdog3 {
	status = "okay";
};
&watchdog_soc0 {
	status = "okay";
};
&watchdog_soc1 {
	status = "okay";
};
&watchdog_soc2 {
	status = "okay";
};
&watchdog_soc3 {
	status = "okay";
};

&watchdog_soc4 {
	bst_wdt_name = "soc_a78_wdt4";
	status = "okay";
};
&watchdog_soc5 {
	bst_wdt_name = "soc_a78_wdt5";
	status = "okay";
};
&watchdog_soc6 {
	bst_wdt_name = "soc_a78_wdt6";
	status = "okay";
};
&watchdog_soc7 {
	bst_wdt_name = "soc_a78_wdt7";
	status = "okay";
};
&watchdog_db0 {
	status = "disable";
};
&watchdog_db1 {
	status = "disable";
};
&watchdog_db2 {
	status = "disable";
};
&watchdog_db3 {
	status = "disable";
};

&lsp0_pwm0 {
	status = "disable";
};
&lsp1_pwm0 {
	status = "disable";
};

&gpio0 {
	status = "okay";
	pinctrl-names = "default";
	pinctrl-0 = <&isp_pinctrl &deser_pinctrl>;
};
&gpio1 {
	status = "okay";
};
&gpio2 {
	status = "okay";
};
&gpio3 {
	status = "okay";
};
&gpio4 {
	status = "okay";
};
&gpio5 {
	status = "okay";
};
&gpio6 {
	status = "okay";
};
&gpio7 {
	status = "okay";
};
&gpiokeys {
	status = "disable";
};
&thermal {
	status = "okay";
};

&can0 {
	status = "okay";
};
&can1 {
	status = "okay";
};

&swdma0 {
	status = "disable";
};

&gdma0 {
	status = "okay";
};

&usb3_phy{
	/delete-property/ host_force_gen1_speed;
};
&usb2_phy{
	/delete-property/ host_force_gen1_speed;
};
&usbdwc3{
	iommus = <&mmu600_soc 1>;
	maximum-speed = "super-speed-plus";
};
&usbdwc2{
	iommus = <&mmu600_soc 2>;
	maximum-speed = "super-speed-plus";
};
&usbdrd_dwc3 {
	status = "okay";
};

&dwc3 {
	status = "okay";
};

&mmc0 {
	memory-region = <&bst_sramemmc0_reserved>;
	status = "okay";
};
&mmc1 {
	status = "okay";
	memory-region = <&bst_sramemmc1_reserved>;
	vqmmc-supply=<&v_qmmc>;
	pinctrl-names = "default";
	pinctrl-0 = <&sd_pinctrl>;

};

&mmu600_pcie {
	status = "okay";
};
&mmu600_codec {
	status = "disable";
};
&mmu600_soc {
	status = "okay";
};
&mmu600_coreip {
	status = "okay";
};

&ufs {
	status = "disable";
};

&pcie_phy {
	dmc-lane = <0x1>; /* bit0: 1=2x2ports, 0=1x4ports */
	dmc-mode = <0x3>; /* (bit1 for ctl0)/(bit0 for ctl1):1=RC-mode, 0=EP-mode */
	pcie-ctl0 = <1>;  /* Controller reset */
	pcie-ctl1 = <1>;  /* Controller reset */
	pcie-ref-clk0 = <1>; /* 0=onchip_clk, 1=pad_clk*/
	pcie-ref-clk1 = <1>; /* 0=onchip_clk, 1=pad_clk, 2=repeat_clk */
};

&pcie0 {
	status = "disable";
	reset-gpio = <&portg 24 GPIO_ACTIVE_HIGH>;
	reset-gpio-active-high;
	iommus = <&mmu600_pcie 0x0>;
	iommu-map = <0x0  &mmu600_pcie 0x00 0x1000>;
};

&pcie1 {
	status = "disable";
	reset-gpio = <&portg 25 GPIO_ACTIVE_HIGH>;
	reset-gpio-active-high;
	iommus = <&mmu600_pcie 0x1000>;
	iommu-map = <0x1000  &mmu600_pcie 0x1000 0x1000>;
};

&codec0 {
	compatible = "codec0 arm china,linlon-v5";
	status = "okay";
};
&codec1 {
	compatible = "arm china,linlon-v5";
	status = "okay";
};

&mipi_dsi0 {
	status = "okay";
};
&mipi_dsi1 {
	status = "okay";
};
&mipi_csr {
	status = "okay";
};

&bst_dptx {
	status = "disable";
pinctrl-names = "default";
    pinctrl-0 = <&hpd_pinctrl>;
};

&xrp0 {
	status = "disable";
};

&bst_dpu0 {
	status = "disable";
	memory-region = <&bst_dpu_reserved>;
};
&bst_dpu2 {
	status = "disable";
	memory-region = <&bst_dpu_reserved>;
};
&bst_dpu1 {
	status = "disable";
	memory-region = <&bst_dpu_reserved>;
};

&lvds_conn {
	status = "disable";
	pinctrl-names = "default";
pinctrl-0 = <&lvds0_pinconfig &lvds1_pinconfig>;
};


&bst_disp_fw {
	status = "okay";
	msgbx-pid = "CPU_0"; /* "CPU_0" - "CPU_3" */
};

&bst_virt_dpu0 {
	status = "okay";
	memory-region = <&bst_dpu_reserved>;
	os-type = "ADAS_LINUX";
	pipeline@0 {
		status = "okay";
		dc-type = "DEVICE_TYPE_VIRT_DC_PIPE2";
		layer-num = <4>;
		port@0 {
			virt_pipe0_out: endpoint@0 {
				remote-endpoint = <&virt_dptx_in>;
			};
		};
	};
	pipeline@1 {
		status = "okay";
		dc-type = "DEVICE_TYPE_VIRT_DC_PIPE0";
		layer-num = <4>;
		port@0 {
			virt_pipe1_out: endpoint@0 {
				remote-endpoint = <&virt_dsi1_in>;
			};
		};
	};
	pipeline@2 {
		status = "okay";
		dc-type = "DEVICE_TYPE_VIRT_DC_PIPE4";
		layer-num = <4>;
		port@0 {
			reg = <0>;
			virt_pipe2_out: endpoint@0 {
				remote-endpoint = <&virt_dsi0_in>;
			};
		};
	};
};

&bst_virt_dptx {
	status = "okay";
	ports {
		port@0 {
			virt_dptx_in: endpoint@0 {
				remote-endpoint = <&virt_pipe0_out>;
			};
		};
	};
};

&bst_virt_dsi0 {
	status = "okay";
	ports {
		port@0 {
			virt_dsi0_in: endpoint@0 {
				remote-endpoint = <&virt_pipe2_out>;
			};
		};
	};
};

&bst_virt_dsi1 {
	status = "okay";
	ports {
		port@0 {
			virt_dsi1_in: endpoint@0 {
				remote-endpoint = <&virt_pipe1_out>;
			};
		};
	};
};

&gpu_ivi {
	status = "disable";
};

&gpu_adas {
	status = "okay";
};

&gpu_db {
	status = "disable";
};

&gpu_dma_buf {
	memory-region = <&gpu_dma_buf_reserved>;
};

&pinctrl {
	status = "disable";
};

&clkc {
	status = "okay";
};

&gtc {
	status = "okay";
};

&xgmac0 {
	status = "okay";
	max-speed = <10000>;
	snps,ps-speed = <10000>;
	phy-handle = <&eth_phy0>;
	extend-op = <20>;
	phy-mode = "sgmii";
	mac-mode = "gmii";
	fpe-hs = <0>;
	xpcs-addr = <0>;
	/*bypass;  //bool, set: bypass , non set : non bypass
	pinctrl-names = "default";
        pinctrl-0 = <&soc_xgmac_pinctrl>;*/
	fixed-link {
		speed = <10000>;
		full-duplex;
		pause;
	};
	mdio {
		compatible = "snps,dwmac-mdio";
		#address-cells = <1>;
		#size-cells = <0>;
		status = "okay";
		eth_phy0: eth_phy0@0 {
			compatible = "marvell,88E1510", "ethernet-phy-id0141.0DD1", "ethernet-phy-ieee802.3-c22";
			device_type = "ethernet-phy";
			max-speed = <1000>;
			reg = <0x1>;
		};

	};
};

&hif {
	status = "disable";
};

&gic600 {
	status = "okay";
};

&its0_x4 {
	status = "okay";
};

&its1_x2 {
	status = "okay";
};

&msgbox {
	status = "okay";
	spi-irq-num = <4>;
	filter-num = <8>;
	// id = <0x0>;
		// end0 and end1 spi irq
	interrupts =    <
			GIC_PPI 2 (GIC_CPU_MASK_SIMPLE(8) | IRQ_TYPE_LEVEL_LOW)
			GIC_PPI 3 (GIC_CPU_MASK_SIMPLE(8) | IRQ_TYPE_LEVEL_LOW)
			GIC_PPI 4 (GIC_CPU_MASK_SIMPLE(8) | IRQ_TYPE_LEVEL_LOW)
			GIC_PPI 15 (GIC_CPU_MASK_SIMPLE(8) | IRQ_TYPE_LEVEL_LOW)
			GIC_SPI 560 (IRQ_TYPE_LEVEL_HIGH)
			GIC_SPI 561 (IRQ_TYPE_LEVEL_HIGH)
			GIC_SPI 562 (IRQ_TYPE_LEVEL_HIGH)
			GIC_SPI 563 (IRQ_TYPE_LEVEL_HIGH)
			GIC_SPI 564 (IRQ_TYPE_LEVEL_HIGH)
			GIC_SPI 565 (IRQ_TYPE_LEVEL_HIGH)
			GIC_SPI 566 (IRQ_TYPE_LEVEL_HIGH)
			GIC_SPI 567 (IRQ_TYPE_LEVEL_HIGH)
			GIC_SPI 568 (IRQ_TYPE_LEVEL_HIGH)
			GIC_SPI 569 (IRQ_TYPE_LEVEL_HIGH)
			GIC_SPI 570 (IRQ_TYPE_LEVEL_HIGH)
			GIC_SPI 571 (IRQ_TYPE_LEVEL_HIGH)
			GIC_SPI 572 (IRQ_TYPE_LEVEL_HIGH)
			GIC_SPI 573 (IRQ_TYPE_LEVEL_HIGH)
			GIC_SPI 574 (IRQ_TYPE_LEVEL_HIGH)
			GIC_SPI 575 (IRQ_TYPE_LEVEL_HIGH)
			>;
	#mbox-cells = <0x1>;
};

&arm_pmu {
	status = "disable";
};

&hwcv {
	status = "okay";
	//memory-region = <&coreip_reserved>;
	use-cvsmm;
};

&ipc {
	status = "okay";
	memory-region = <&bst_ipc_reserved>;
};
&mbox {
	status = "okay";
	memory-region = <&bst_ipc_reserved>;
};
&bst_cvsmm {
	status = "okay";
	iommus = <&mmu600_coreip 2>;
	dma-coherent;
};
&bstn {
	status = "okay";
	memory-region = <&coreip_reserved>;
	//iommus = <&mmu600_coreip 1>,<&mmu600_coreip 4>;
	//dma-coherent;
};
&lwnn {
	status = "okay";
	memory-region = <&coreip_reserved>;
};
&cv {
	status = "disable";
	memory-region = <&bst_cv_reserved>;
};
